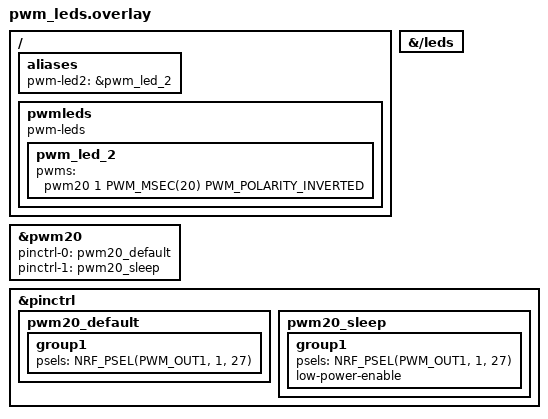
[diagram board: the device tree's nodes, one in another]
/* ========================================================================= */
/*  PWM LED2 Additions (Fully Routed to Channel 1 / P1.27)                   */
/* ========================================================================= */

/* 1. Clear the broken aliases and both GPIO node targets */
/ {
	aliases {
		/delete-property/ led2;
		/delete-property/ led3;      /* Disables standard driver takeover for LED 3 */
		pwm-led2 = &pwm_led_2;
	};
};

&{/leds} {
	/delete-node/ led_2;
	/delete-node/ led_3;             /* Completely frees P1.28 and prevents bleeding */
};

/* 2. Bind custom Node Label targeting Channel 1 */
/ {
	pwmleds {
		compatible = "pwm-leds";
		pwm_led_2: pwm_led_2 {
			/* Changed from channel index 0 to 1 to target the correct hardware line */
			pwms = <&pwm20 1 PWM_MSEC(20) PWM_POLARITY_INVERTED>;
		};
	};
};

/* 3. Configure the active status and pin tracking properties for the PWM20 peripheral */
&pwm20 {
	status = "okay";
	pinctrl-0 = <&pwm20_default>;
	pinctrl-1 = <&pwm20_sleep>;
	pinctrl-names = "default", "sleep";
};

/* 4. Complete pin control definitions mapping PWM Output Channel 1 directly to P1.27 */
&pinctrl {
	pwm20_default: pwm20_default {
		group1 {
			/* Route OUT1 directly to Port 1 Pin 27 (LED 2) */
			psels = <NRF_PSEL(PWM_OUT1, 1, 27)>;
		};
	};

	pwm20_sleep: pwm20_sleep {
		group1 {
			psels = <NRF_PSEL(PWM_OUT1, 1, 27)>;
			low-power-enable;
		};
	};
};
